# STM32F40x register map
File version: 1.5
CPU: CM4 r1p1, little endian, no MPU, FPU, VTOR, 4 interrupt priority bits
Registers are 32-bit, read-write, reset 0x0 unless marked. A register's access mark holds for its fields unless they carry their own. Offsets are from the block's base; [hi:lo] are bit positions; {n}, {i} and the like mark numbered series.

## GPIOA — General-purpose I/Os
Base 0x40020000
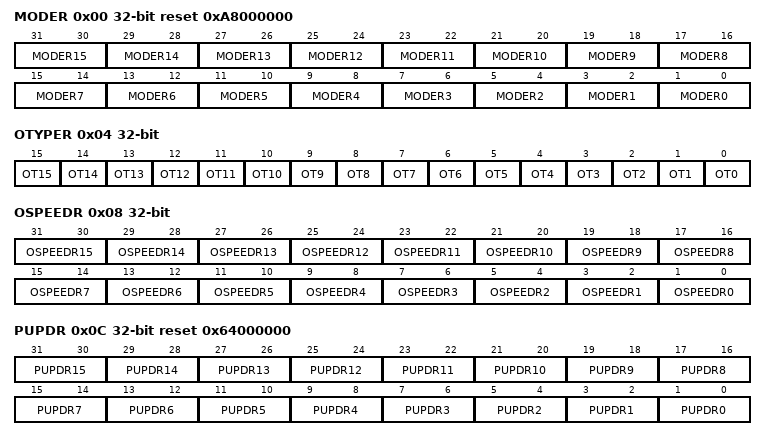
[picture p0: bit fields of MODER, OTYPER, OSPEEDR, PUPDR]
0x00 MODER reset 0xA8000000 — GPIO port mode register
  [all] fields
    0=Input mode (reset state); 1=Output (General purpose output mode); 2=Alternate function mode; 3=Analog mode
  [2n+1:2n] MODER{n} (n=0..15) — Port x configuration bits (y = 0..15)
0x04 OTYPER — GPIO port output type register
  [n] OT{n} (n=0..15) — Port x configuration bits (y = 0..15)
0x08 OSPEEDR — GPIO port output speed register
  [2n+1:2n] OSPEEDR{n} (n=0..15) — Port x configuration bits (y = 0..15)
0x0C PUPDR reset 0x64000000 — GPIO port pull-up/pull-down register
  [2n+1:2n] PUPDR{n} (n=0..15) — Port x configuration bits (y = 0..15)
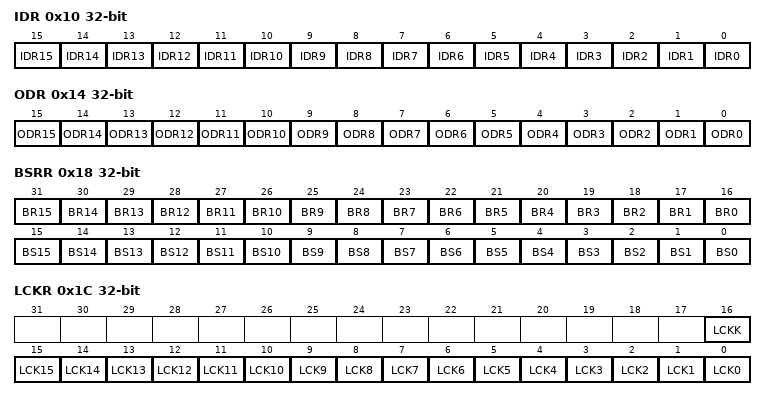
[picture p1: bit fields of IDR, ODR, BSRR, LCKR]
0x10 IDR ro — GPIO port input data register
  [n] IDR{n} (n=0..15) — Port input data (y = 0..15)
0x14 ODR — GPIO port output data register
  [n] ODR{n} (n=0..15) — Port output data (y = 0..15)
0x18 BSRR wo — GPIO port bit set/reset register
  [n+16] BR{n} (n=1..15) — Port x reset bit y (y = 0..15)
    on write: 1=Resets the corresponding ODRx bit
  [16] BR0 — Port x set bit y (y= 0..15)
    on write: 1=Resets the corresponding ODRx bit
  [n] BS{n} (n=0..15) — Port x set bit y (y= 0..15)
    on write: 1=Set (Sets the corresponding ODRx bit)
0x1C LCKR — GPIO port configuration lock register
  [16] LCKK — Port x lock bit y (y= 0..15)
  [n] LCK{n} (n=0..15) — Port x lock bit y (y= 0..15)
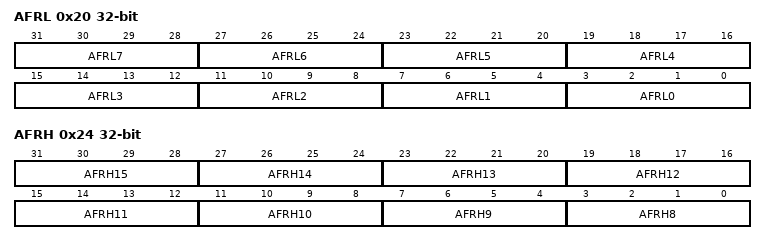
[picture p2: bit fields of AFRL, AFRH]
0x20 AFRL — GPIO alternate function low register
  [31:28] AFRL7 — Alternate function selection for port x bit y (y = 0..7)
    1=TIM1_CH1N; 2=TIM3_CH2; 3=TIM8_CH1N; 5=SPI1_MOSI; 9=TIM14_CH1; 11=ETH_MII_RX_DV_ETH_RMMI_CRS_DV; 15=EVENTOUT
  [27:24] AFRL6 — Alternate function selection for port x bit y (y = 0..7)
    1=TIM1_BKIN; 2=TIM3_CH1; 3=TIM8_BKIN; 5=SPI1_MISO; 9=TIM13_CH1; 13=DCMI_PIXCK; 15=EVENTOUT
  [23:20] AFRL5 — Alternate function selection for port x bit y (y = 0..7)
    1=TIM2_CH1_ETR; 3=TIM8_CH1N; 5=SPI1_SCK; 10=OTG_HS_ULPI_CK; 15=EVENTOUT
  [19:16] AFRL4 — Alternate function selection for port x bit y (y = 0..7)
    5=SPI1_NSS; 6=SPI3_NSS_I2S3_WS; 7=USART2_CK; 12=OTG_HS_SOF; 13=DCMI_HSYNC; 15=EVENTOUT
  [15:12] AFRL3 — Alternate function selection for port x bit y (y = 0..7)
    1=TIM2_CH4; 2=TIM5_CH5; 3=TIM9_CH2; 7=USART2_RX; 10=OTG_HS_ULPI_D0; 11=ETH_MII_COL; 15=EVENTOUT
  [11:8] AFRL2 — Alternate function selection for port x bit y (y = 0..7)
    1=TIM2_CH3; 2=TIM5_CH3; 3=TIM9_CH1; 7=USART2_TX; 11=ETH_MDIO; 15=EVENTOUT
  [7:4] AFRL1 — Alternate function selection for port x bit y (y = 0..7)
    1=TIM2_CH2; 2=TIM5_CH2; 7=USART2_RTS; 8=UART4_RX; 11=ETH_MII_RX_CLK_ETH_RMII_REF_CLK; 15=EVENTOUT
  [3:0] AFRL0 — Alternate function selection for port x bit y (y = 0..7)
    1=TIM2_CH1_ETR; 2=TIM5_CH1; 3=TIM8_ETR; 7=USART2_CTS; 8=UART4_TX; 11=ETH_MII_CRS; 15=EVENTOUT
0x24 AFRH — GPIO alternate function high register
  [31:28] AFRH15 — Alternate function selection for port x bit y (y = 8..15)
    0=JTDI; 1=TIM2_CH1_TIM2_ETR; 5=SPI1_NSS; 6=SPI3_NSS_I2S3_WS; 15=EVENTOUT
  [27:24] AFRH14 — Alternate function selection for port x bit y (y = 8..15)
    0=JTCK_SWDCLK; 15=EVENTOUT
  [23:20] AFRH13 — Alternate function selection for port x bit y (y = 8..15)
    0=JTMS_SWDIO; 15=EVENTOUT
  [19:16] AFRH12 — Alternate function selection for port x bit y (y = 8..15)
    1=TIM1_ETR; 7=USART1_RTS; 9=CAN1_TX; 10=OTG_FS_DP; 15=EVENTOUT
  [15:12] AFRH11 — Alternate function selection for port x bit y (y = 8..15)
    1=TIM1_CH4; 7=USART1_CTS; 9=CAN1_RX; 10=OTG_FS_DM; 15=EVENTOUT
  [11:8] AFRH10 — Alternate function selection for port x bit y (y = 8..15)
    1=TIM1_CH3; 7=USART1_RX; 10=OTG_FS_ID; 13=DCMI_D1; 15=EVENTOUT
  [7:4] AFRH9 — Alternate function selection for port x bit y (y = 8..15)
    1=TIM1_CH2; 4=I2C3_SMBA; 7=USART1_TX; 13=DCMI_D0; 15=EVENTOUT
  [3:0] AFRH8 — Alternate function selection for port x bit y (y = 8..15)
    0=MCO1; 1=TIM1_CH1; 4=I2C3_SCL; 7=USART1_CK; 10=OTG_FS_SOF; 15=EVENTOUT
